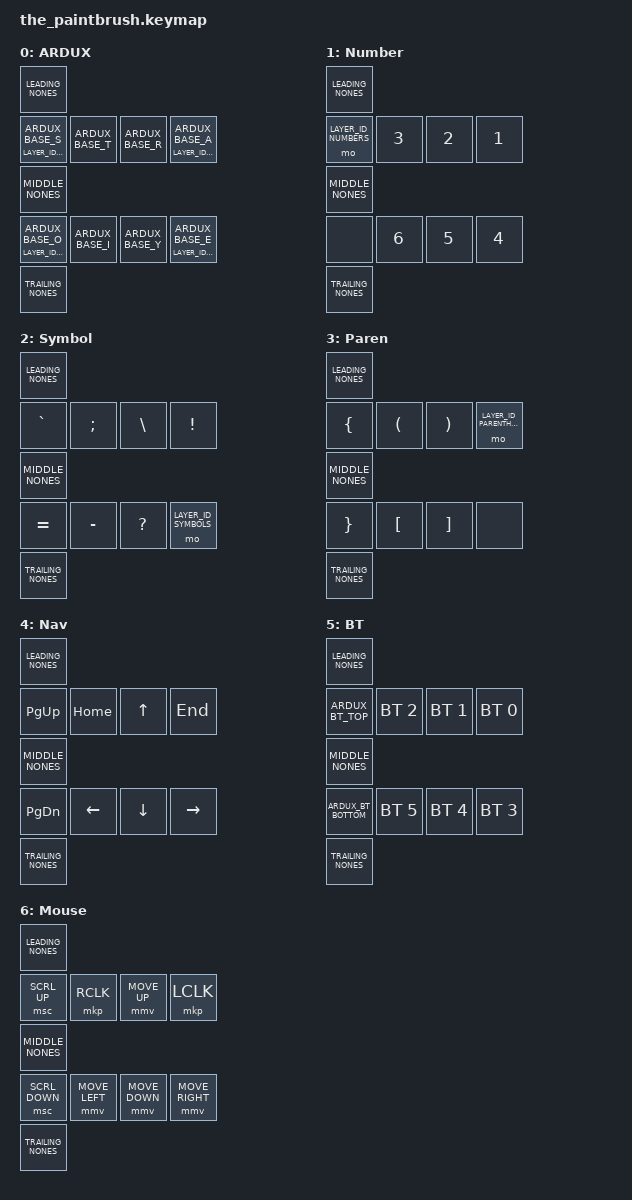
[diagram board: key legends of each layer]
/*
 * Copyright (c) 2020 The ZMK Contributors
 *
 * SPDX-License-Identifier: MIT
 */

#include <behaviors.dtsi>
#include <dt-bindings/zmk/keys.h>
#include <dt-bindings/zmk/bt.h>
#include <dt-bindings/zmk/pointing.h>

// Left/Right
#define ARDUX_LEFT 1

// ARTS Row
#define KEY_A 3
#define KEY_R 2
#define KEY_T 1
#define KEY_S 0
// EYIO Row
#define KEY_E 7
#define KEY_Y 6
#define KEY_I 5
#define KEY_O 4

// Define Offsets
#define LEADING_NONES NONE(0,0,0)
#define MIDDLE_NONES NONE(0, 0, 0)
#define TRAILING_NONES NONE(0, 0, 0)

/*****************************************
 * Macros for filling in "&none" in the right places in the keymap for re-use needs
 *****************************************/
#define NONE0(X)
#define NONE1(X) X
#define NONE2(X) NONE1(X) X
#define NONE3(X) NONE2(X) X
#define NONE4(X) NONE3(X) X
#define NONE5(X) NONE4(X) X
#define NONE6(X) NONE5(X) X
#define NONE7(X) NONE6(X) X
#define NONE8(X) NONE7(X) X
#define NONE9(X) NONE8(X) X
#define NONE10(X) NONE9(X) X

#define NONE(HUNDREDS,TENS,ONES) \
  NONE##HUNDREDS(NONE10(NONE10(&none))) \
  NONE##TENS(NONE10(&none)) \
  NONE##ONES(&none)

#if !defined ARDUX_LAYER_CUSTOM
#define ARDUX_LAYER_CUSTOM                                            \
		custom {                                                       \
		    	display-name = "Custom";                                          \
    			bindings = <                                               \
				      LEADING_NONES                                          \
				      &none               &kp C_VOL_UP  &kp INS   &kp C_MUTE \
				      MIDDLE_NONES                                           \
				      &mo LAYER_ID_CUSTOM &kp C_VOL_DN  &kp PSCRN &sk RSHFT  \
				      TRAILING_NONES                                         \
			    >;                                                         \
		  };
#endif


/*****************************************
 * Layer IDs used by the ARDUX keymap
 * Do NOT change these and do NOT change the order of the layers as shown below
 *****************************************/
#define ARDUX_BASE_A A
#define ARDUX_BASE_R R
#define ARDUX_BASE_T T
#define ARDUX_BASE_S S
#define ARDUX_BASE_E E
#define ARDUX_BASE_Y Y
#define ARDUX_BASE_I I
#define ARDUX_BASE_O O
#define ARDUX_COMBO_N N

#define LAYER_ID_GLOBAL -1
#define LAYER_ID_BASE 0
#define LAYER_ID_NUMBERS 1
#define LAYER_ID_SYMBOLS 2
#define LAYER_ID_PARENTHETICALS 3
#define LAYER_ID_NAVIGATION 4
#define LAYER_ID_BT_SEL 5
#define LAYER_ID_MOUSE 6
#define LAYER_ID_CUSTOM 7

/*****************************************
 * Standard ARDUX combo definitions
 * These should NOT be changed and are global in scope
 *****************************************/
/ {
	combos {
		compatible = "zmk,combos";
		/*****************************************
		 * 2 key combos
		 *****************************************/
		// Function layer doesn't apply to non-big ardux presently
		#if defined ARDUX_BIG
		combo_layer_functions { key-positions = <KEY_F_TOP KEY_F_BOTTOM>; bindings = <&sl LAYER_ID_BIG_FUNCTION>; };
		#endif
		combo_enter      { timeout-ms = <TIMEOUT_COMBO_2>; key-positions = <KEY_A KEY_E>; bindings = <&kp ENTER>; };
		combo_control    { timeout-ms = <TIMEOUT_COMBO_2>; key-positions = <KEY_E KEY_S>; bindings = <&sk LCTRL>; };
		combo_gui        { timeout-ms = <TIMEOUT_COMBO_2>; key-positions = <KEY_Y KEY_S>; bindings = <&sk LGUI>; };
		combo_alt        { timeout-ms = <TIMEOUT_COMBO_2>; key-positions = <KEY_I KEY_S>; bindings = <&sk LALT>; };
		combo_backspace  { timeout-ms = <TIMEOUT_COMBO_2>; key-positions = <KEY_E KEY_R>; bindings = <&kp BACKSPACE>; };
		combo_delete     { timeout-ms = <TIMEOUT_COMBO_2>; key-positions = <KEY_I KEY_R>; bindings = <&kp DELETE>; };
		combo_shift_lock { timeout-ms = <TIMEOUT_COMBO_2>; key-positions = <KEY_R KEY_Y>; bindings = <&kt LSHFT>; };

		combo_b           { layers = <LAYER_ID_BASE>; timeout-ms = <TIMEOUT_COMBO_2>; key-positions = <KEY_E KEY_O>; bindings = <&kp B>; };
		combo_c           { layers = <LAYER_ID_BASE>; timeout-ms = <TIMEOUT_COMBO_2>; key-positions = <KEY_E KEY_Y>; bindings = <&kp C>; };
		combo_n           { layers = <LAYER_ID_BASE>; timeout-ms = <TIMEOUT_COMBO_2>; key-positions = <KEY_I KEY_O>; bindings = <&kp ARDUX_COMBO_N>; };
		combo_f           { layers = <LAYER_ID_BASE>; timeout-ms = <TIMEOUT_COMBO_2>; key-positions = <KEY_A KEY_R>; bindings = <&kp F>; };
		combo_g           { layers = <LAYER_ID_BASE>; timeout-ms = <TIMEOUT_COMBO_2>; key-positions = <KEY_R KEY_T>; bindings = <&kp G>; };
		combo_u           { layers = <LAYER_ID_BASE>; timeout-ms = <TIMEOUT_COMBO_2>; key-positions = <KEY_Y KEY_I>; bindings = <&kp U>; };
		combo_h           { layers = <LAYER_ID_BASE>; timeout-ms = <TIMEOUT_COMBO_2>; key-positions = <KEY_E KEY_I>; bindings = <&kp H>; };
		combo_v           { layers = <LAYER_ID_BASE>; timeout-ms = <TIMEOUT_COMBO_2>; key-positions = <KEY_R KEY_S>; bindings = <&kp V>; };
		combo_j           { layers = <LAYER_ID_BASE>; timeout-ms = <TIMEOUT_COMBO_2>; key-positions = <KEY_T KEY_S>; bindings = <&kp J>; };
		combo_w           { layers = <LAYER_ID_BASE>; timeout-ms = <TIMEOUT_COMBO_2>; key-positions = <KEY_A KEY_S>; bindings = <&kp W>; };
		combo_k           { layers = <LAYER_ID_BASE>; timeout-ms = <TIMEOUT_COMBO_2>; key-positions = <KEY_Y KEY_O>; bindings = <&kp K>; };
		combo_period       { layers = <LAYER_ID_BASE>; timeout-ms = <TIMEOUT_COMBO_2>; key-positions = <KEY_A KEY_Y>; bindings = <&kp PERIOD>; };
		combo_comma       { layers = <LAYER_ID_BASE>; timeout-ms = <TIMEOUT_COMBO_2>; key-positions = <KEY_A KEY_I>; bindings = <&kp COMMA>; };
		combo_slash       { layers = <LAYER_ID_BASE>; timeout-ms = <TIMEOUT_COMBO_2>; key-positions = <KEY_A KEY_O>; bindings = <&kp SLASH>; };
		combo_exclamation { layers = <LAYER_ID_BASE>; timeout-ms = <TIMEOUT_COMBO_2>; key-positions = <KEY_T KEY_I>; bindings = <&kp EXCL>; };
		
		combo_seven { layers = <LAYER_ID_NUMBERS>; timeout-ms = <TIMEOUT_COMBO_2>; key-positions = <KEY_A KEY_R>; bindings = <&kp N7>; };
		combo_eight { layers = <LAYER_ID_NUMBERS>; timeout-ms = <TIMEOUT_COMBO_2>; key-positions = <KEY_R KEY_T>; bindings = <&kp N8>; };
		combo_nine  { layers = <LAYER_ID_NUMBERS>; timeout-ms = <TIMEOUT_COMBO_2>; key-positions = <KEY_E KEY_Y>; bindings = <&kp N9>; };
		combo_zero  { layers = <LAYER_ID_NUMBERS>; timeout-ms = <TIMEOUT_COMBO_2>; key-positions = <KEY_Y KEY_I>; bindings = <&kp N0>; };

		/*****************************************
		 * 3 key combos
		 *****************************************/
		combo_esc              { timeout-ms = <TIMEOUT_COMBO_3>; key-positions = <KEY_A KEY_R KEY_O>; bindings = <&kp ESC>; };
		combo_layer_navigation { timeout-ms = <TIMEOUT_COMBO_3>; key-positions = <KEY_R KEY_E KEY_I>; bindings = <&tog LAYER_ID_NAVIGATION>; };
		combo_layer_mouse { timeout-ms = <TIMEOUT_COMBO_3>; key-positions = <KEY_A KEY_T KEY_Y>; bindings = <&tog LAYER_ID_MOUSE>; };

		combo_m            { layers = <LAYER_ID_BASE>; timeout-ms = <TIMEOUT_COMBO_3>; key-positions = <KEY_Y KEY_I KEY_O>; bindings = <&kp M>; };
		combo_d            { layers = <LAYER_ID_BASE>; timeout-ms = <TIMEOUT_COMBO_3>; key-positions = <KEY_A KEY_R KEY_T>; bindings = <&kp D>; };
		combo_p            { layers = <LAYER_ID_BASE>; timeout-ms = <TIMEOUT_COMBO_3>; key-positions = <KEY_E KEY_I KEY_O>; bindings = <&kp P>; };
		combo_q            { layers = <LAYER_ID_BASE>; timeout-ms = <TIMEOUT_COMBO_3>; key-positions = <KEY_A KEY_T KEY_S>; bindings = <&kp Q>; };
		combo_x            { layers = <LAYER_ID_BASE>; timeout-ms = <TIMEOUT_COMBO_3>; key-positions = <KEY_R KEY_T KEY_S>; bindings = <&kp X>; };
		combo_l            { layers = <LAYER_ID_BASE>; timeout-ms = <TIMEOUT_COMBO_3>; key-positions = <KEY_E KEY_Y KEY_I>; bindings = <&kp L>; };
		combo_single_quote { layers = <LAYER_ID_BASE>; timeout-ms = <TIMEOUT_COMBO_3>; key-positions = <KEY_A KEY_Y KEY_I>; bindings = <&kp SQT>; };
		
		/*****************************************
		 * 4 key combos
		 *****************************************/
		combo_tab             { timeout-ms = <TIMEOUT_COMBO_4>; key-positions = <KEY_A KEY_R KEY_T KEY_O>; bindings = <&kp TAB>; };
		combo_space           { timeout-ms = <TIMEOUT_COMBO_4>; key-positions = <KEY_E KEY_Y KEY_I KEY_O>; bindings = <&kp SPACE>; };
		combo_shift           { timeout-ms = <TIMEOUT_COMBO_4>; key-positions = <KEY_E KEY_R KEY_T KEY_S>; bindings = <&sk LSHFT>; };
		combo_layer_bt_select { timeout-ms = <TIMEOUT_COMBO_4>; key-positions = <KEY_A KEY_E KEY_S KEY_O>; bindings = <&tog LAYER_ID_BT_SEL>; };
		combo_bt_clr          { timeout-ms = <TIMEOUT_COMBO_4>; key-positions = <KEY_R KEY_Y KEY_T KEY_I>; bindings = <&bt BT_CLR>; };

		combo_z         { layers = <LAYER_ID_BASE>; timeout-ms = <TIMEOUT_COMBO_4>; key-positions = <KEY_A KEY_R KEY_T KEY_S>; bindings = <&kp Z>; };
		combo_caps_lock { layers = <LAYER_ID_BASE>; timeout-ms = <TIMEOUT_COMBO_4>; key-positions = <KEY_O KEY_I KEY_Y KEY_A>; bindings = <&kp CAPS>; };
	};
};

/*****************************************
 * Standard ARDUX layer activation definitions
 * These should NOT be changed and are global in scope
 *****************************************/
/ {
	behaviors {
		layer_base_kp: layer_base_kp { compatible = "zmk,behavior-hold-tap"; display-name = "layer_base_kp";
						#binding-cells = <2>; tapping-term-ms = <TIMEOUT_LAYER_HOLD>; flavor = "tap-preferred";
						bindings = <&mo>, <&kp>; };
		layer_numbers_kp: layer_numbers_kp { compatible = "zmk,behavior-hold-tap"; display-name = "layer_numbers_kp";
						#binding-cells = <2>; tapping-term-ms = <TIMEOUT_LAYER_HOLD>; flavor = "tap-preferred";
						bindings = <&mo>, <&kp>; };
		layer_symbols_kp: layer_symbols_kp { compatible = "zmk,behavior-hold-tap"; display-name = "layer_symbols_kp";
						#binding-cells = <2>; tapping-term-ms = <TIMEOUT_LAYER_HOLD>; flavor = "tap-preferred";
						bindings = <&mo>, <&kp>; };
		layer_parentheticals_kp: layer_parentheticals_kp { compatible = "zmk,behavior-hold-tap"; display-name = "layer_parentheticals_kp";
						#binding-cells = <2>; tapping-term-ms = <TIMEOUT_LAYER_HOLD>; flavor = "tap-preferred";
						bindings = <&mo>, <&kp>; };
		layer_custom_kp: layer_custom_kp { compatible = "zmk,behavior-hold-tap"; display-name = "layer_custom_kp";
						#binding-cells = <2>; tapping-term-ms = <TIMEOUT_LAYER_HOLD>; flavor = "tap-preferred";
						bindings = <&mo>, <&kp>; };
		ctrl_alt_kp: ctrl_alt_kp { compatible = "zmk,behavior-hold-tap"; display-name = "ctrl_alt_kp";
						#binding-cells = <2>; tapping-term-ms = <TIMEOUT_LAYER_HOLD>; flavor = "tap-preferred";
						bindings = <&sk>, <&sk>; };
	};
};
/*****************************************
 * Standard ARDUX layer definitions
 * !!!!!!!!!! FOR LEFT HANDED USE !!!!!!!!!!
 *****************************************/
/ {
	keymap {
		compatible = "zmk,keymap";
		base {
			display-name = "ARDUX";
			bindings = <
				LEADING_NONES
				&layer_numbers_kp LAYER_ID_NUMBERS ARDUX_BASE_S        &kp ARDUX_BASE_T     &kp ARDUX_BASE_R     &layer_parentheticals_kp LAYER_ID_PARENTHETICALS ARDUX_BASE_A
				MIDDLE_NONES
				&layer_custom_kp LAYER_ID_CUSTOM ARDUX_BASE_O          &kp ARDUX_BASE_I     &kp ARDUX_BASE_Y     &layer_symbols_kp LAYER_ID_SYMBOLS ARDUX_BASE_E
				TRAILING_NONES
			>;
		};
		numbers {
			display-name = "Number";
			bindings = <
				LEADING_NONES
				&mo LAYER_ID_NUMBERS                        &kp N3    &kp N2    &kp N1
				MIDDLE_NONES
				&none                                       &kp N6    &kp N5    &kp N4
				TRAILING_NONES
			>;
		};
		symbols {
			display-name = "Symbol";
			bindings = <
				LEADING_NONES
				&kp GRAVE                                   &kp SEMI  &kp BSLH  &kp EXCL
				MIDDLE_NONES
				&kp EQUAL                                   &kp MINUS &kp QMARK &mo LAYER_ID_SYMBOLS
				TRAILING_NONES
			>;
		};
		parentheticals {
			display-name = "Paren";
			bindings = <
				LEADING_NONES
				&kp LBRC                                    &kp LPAR  &kp RPAR  &mo LAYER_ID_PARENTHETICALS
				MIDDLE_NONES
				&kp RBRC                                    &kp LBKT  &kp RBKT  &none
				TRAILING_NONES
			>;
		};
		navigation {
			display-name = "Nav";
			bindings = <
				LEADING_NONES
				&kp PG_UP                                   &kp HOME  &kp UP    &kp END
				MIDDLE_NONES
				&kp PG_DN                                   &kp LEFT  &kp DOWN  &kp RIGHT
				TRAILING_NONES
			>;
		};
		bt {
			display-name = "BT";
			bindings = <
				LEADING_NONES
				ARDUX_BT_TOP    &bt BT_SEL 2 &bt BT_SEL 1 &bt BT_SEL 0
				MIDDLE_NONES
				ARDUX_BT_BOTTOM &bt BT_SEL 5 &bt BT_SEL 4 &bt BT_SEL 3
				TRAILING_NONES
			>;
		};
		mouse {
			display-name = "Mouse";
			bindings = <
				LEADING_NONES
				&msc SCRL_UP                                     &mkp RCLK       &mmv MOVE_UP    &mkp LCLK
				MIDDLE_NONES
				&msc SCRL_DOWN                                   &mmv MOVE_LEFT  &mmv MOVE_DOWN  &mmv MOVE_RIGHT
				TRAILING_NONES
			>;
		};
		ARDUX_LAYER_CUSTOM
	};
